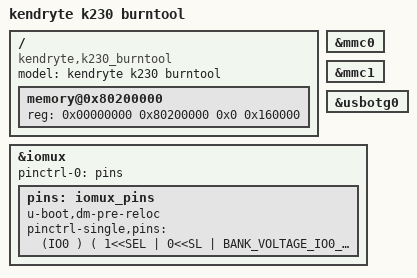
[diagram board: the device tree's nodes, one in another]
/* Copyright (c) 2023, Canaan Bright Sight Co., Ltd
 *
 * Redistribution and use in source and binary forms, with or without
 * modification, are permitted provided that the following conditions are met:
 * 1. Redistributions of source code must retain the above copyright
 * notice, this list of conditions and the following disclaimer.
 * 2. Redistributions in binary form must reproduce the above copyright
 * notice, this list of conditions and the following disclaimer in the
 * documentation and/or other materials provided with the distribution.
 *
 * THIS SOFTWARE IS PROVIDED BY THE COPYRIGHT HOLDERS AND
 * CONTRIBUTORS "AS IS" AND ANY EXPRESS OR IMPLIED WARRANTIES,
 * INCLUDING, BUT NOT LIMITED TO, THE IMPLIED WARRANTIES OF
 * MERCHANTABILITY AND FITNESS FOR A PARTICULAR PURPOSE ARE
 * DISCLAIMED. IN NO EVENT SHALL THE COPYRIGHT HOLDER OR
 * CONTRIBUTORS BE LIABLE FOR ANY DIRECT, INDIRECT, INCIDENTAL,
 * SPECIAL, EXEMPLARY, OR CONSEQUENTIAL DAMAGES (INCLUDING,
 * BUT NOT LIMITED TO, PROCUREMENT OF SUBSTITUTE GOODS OR
 * SERVICES; LOSS OF USE, DATA, OR PROFITS; OR BUSINESS
 * INTERRUPTION) HOWEVER CAUSED AND ON ANY THEORY OF LIABILITY,
 * WHETHER IN CONTRACT, STRICT LIABILITY, OR TORT (INCLUDING
 * NEGLIGENCE OR OTHERWISE) ARISING IN ANY WAY OUT OF THE USE
 * OF THIS SOFTWARE, EVEN IF ADVISED OF THE POSSIBILITY OF SUCH DAMAGE.
 */
/dts-v1/;

#include <dt-bindings/pinctrl/k230-pinctrl.h>

#define BANK_VOLTAGE_IO0_IO1	 K230_MSC_1V8  // FIXED
#define BANK_VOLTAGE_IO2_IO13	 K230_MSC_3V3
#define BANK_VOLTAGE_IO14_IO25	 K230_MSC_3V3
#define BANK_VOLTAGE_IO26_IO37	 K230_MSC_3V3
#define BANK_VOLTAGE_IO38_IO49	 K230_MSC_3V3
#define BANK_VOLTAGE_IO50_IO61	 K230_MSC_3V3
#define BANK_VOLTAGE_IO62_IO63	 K230_MSC_3V3

#include "k230.dtsi"

/ {
	model = "kendryte k230 burntool";
	compatible = "kendryte,k230_burntool";

    memory@0x80200000 {
        device_type = "memory";
        reg = <0x00000000 0x80200000 0x0 0x160000>;
    };
};

&mmc0 {
	status = "okay";
};

&mmc1 {
	status = "okay";
};

&usbotg0 {
	status = "okay";
};

&iomux {
	pinctrl-names = "default";
	pinctrl-0 = <&pins>;

//	Please pay attention to the bank voltage! will damage the chip.
	pins: iomux_pins {
		u-boot,dm-pre-reloc;
		pinctrl-single,pins = <

		// boot
		(IO0 ) ( 1<<SEL | 0<<SL | BANK_VOLTAGE_IO0_IO1 <<MSC | 0<<IE | 1<<OE | 1<<PU | 0<<PD | 2<<DS | 0<<ST )
		// boot1
		(IO1 ) ( 1<<SEL | 0<<SL | BANK_VOLTAGE_IO0_IO1 <<MSC | 0<<IE | 1<<OE | 1<<PU | 0<<PD | 2<<DS | 0<<ST )

		// UART0_TXD
		(IO38) ( 1<<SEL | 0<<SL | BANK_VOLTAGE_IO38_IO49<<MSC | 0<<IE | 1<<OE | 0<<PU | 0<<PD | 7<<DS | 1<<ST )
		// UART0_RXD
		(IO39) ( 1<<SEL | 0<<SL | BANK_VOLTAGE_IO38_IO49<<MSC | 1<<IE | 0<<OE | 0<<PU | 0<<PD | 7<<DS | 1<<ST )
		>;
	};
};
